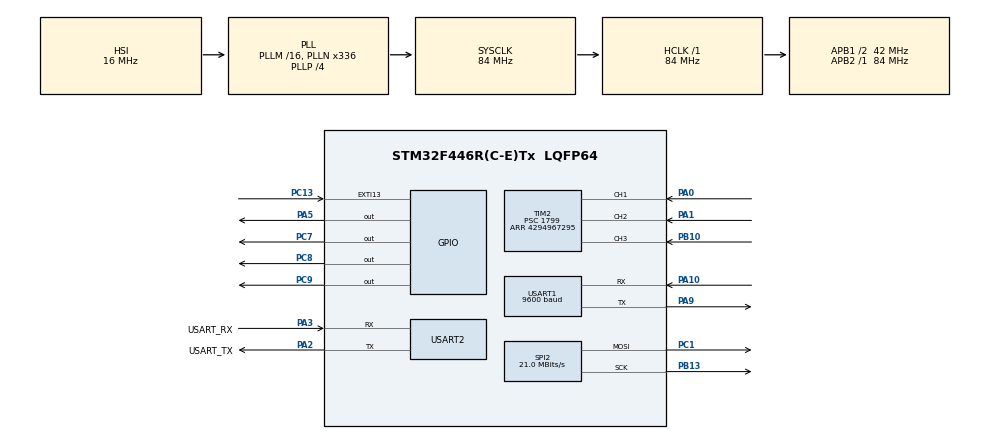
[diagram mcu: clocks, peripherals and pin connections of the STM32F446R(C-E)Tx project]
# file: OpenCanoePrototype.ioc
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Dma.Request0=USART2_TX
Dma.Request1=USART1_RX
Dma.USART1_RX.1.Direction=DMA_PERIPH_TO_MEMORY
Dma.USART1_RX.1.FIFOMode=DMA_FIFOMODE_DISABLE
Dma.USART1_RX.1.Instance=DMA2_Stream2
Dma.USART1_RX.1.MemDataAlignment=DMA_MDATAALIGN_BYTE
Dma.USART1_RX.1.MemInc=DMA_MINC_ENABLE
Dma.USART1_RX.1.Mode=DMA_CIRCULAR
Dma.USART1_RX.1.PeriphDataAlignment=DMA_PDATAALIGN_BYTE
Dma.USART1_RX.1.PeriphInc=DMA_PINC_DISABLE
Dma.USART1_RX.1.Priority=DMA_PRIORITY_LOW
Dma.USART2_TX.0.Direction=DMA_MEMORY_TO_PERIPH
Dma.USART2_TX.0.FIFOMode=DMA_FIFOMODE_DISABLE
Dma.USART2_TX.0.Instance=DMA1_Stream6
Dma.USART2_TX.0.MemDataAlignment=DMA_MDATAALIGN_BYTE
Dma.USART2_TX.0.MemInc=DMA_MINC_ENABLE
Dma.USART2_TX.0.Mode=DMA_NORMAL
Dma.USART2_TX.0.PeriphDataAlignment=DMA_PDATAALIGN_BYTE
Dma.USART2_TX.0.PeriphInc=DMA_PINC_DISABLE
Dma.USART2_TX.0.Priority=DMA_PRIORITY_LOW
Mcu.Family=STM32F4
Mcu.Name=STM32F446R(C-E)Tx
Mcu.Package=LQFP64
NUCLEO-F446RE.BUTTON=1
NUCLEO-F446RE.LD1=true
NVIC.DMA1_Stream6_IRQn=true\:0\:0\:false\:false\:true\:false\:true\:true
NVIC.DMA2_Stream2_IRQn=true\:0\:0\:false\:false\:true\:false\:true\:true
NVIC.EXTI15_10_IRQn=true\:0\:0\:false\:false\:true\:false\:true\:true
NVIC.PriorityGroup=NVIC_PRIORITYGROUP_0
NVIC.TIM2_IRQn=true\:0\:0\:false\:false\:true\:true\:true\:true
NVIC.USART1_IRQn=true\:0\:0\:false\:false\:true\:true\:true\:true
NVIC.USART2_IRQn=true\:0\:0\:false\:false\:true\:true\:true\:true
PA0-WKUP.GPIO_PuPd=GPIO_PULLDOWN
PA0-WKUP.Signal=S_TIM2_CH1_ETR
PA1.GPIO_PuPd=GPIO_PULLDOWN
PA1.Signal=S_TIM2_CH2
PA10.Mode=Asynchronous
PA10.Signal=USART1_RX
PA13.GPIO_Label=TMS
PA13.Signal=SYS_JTMS-SWDIO
PA14.GPIO_Label=TCK
PA14.Signal=SYS_JTCK-SWCLK
PA2.GPIO_Label=USART_TX
PA2.Mode=Asynchronous
PA2.Signal=USART2_TX
PA3.GPIO_Label=USART_RX
PA3.Mode=Asynchronous
PA3.Signal=USART2_RX
PA5.Signal=GPIO_Output
PA9.Mode=Asynchronous
PA9.Signal=USART1_TX
PB10.GPIO_PuPd=GPIO_PULLDOWN
PB10.Signal=S_TIM2_CH3
PB13.Mode=TX_Only_Simplex_Unidirect_Master
PB13.Signal=SPI2_SCK
PB3.GPIO_Label=SWO
PB3.Signal=SYS_JTDO-SWO
PC1.Mode=TX_Only_Simplex_Unidirect_Master
PC1.Signal=SPI2_MOSI
PC13.Signal=GPXTI13
PC14-OSC32_IN.Signal=RCC_OSC32_IN
PC15-OSC32_OUT.Signal=RCC_OSC32_OUT
PC7.Signal=GPIO_Output
PC8.Signal=GPIO_Output
PC9.Signal=GPIO_Output
PH0-OSC_IN.Signal=RCC_OSC_IN
PH1-OSC_OUT.Signal=RCC_OSC_OUT
ProjectManager.HeapSize=0x200
ProjectManager.StackSize=0x400
ProjectManager.TargetToolchain=CMake
RCC.AHBFreq_Value=84000000
RCC.APB1CLKDivider=RCC_HCLK_DIV2
RCC.APB1Freq_Value=42000000
RCC.APB1TimFreq_Value=84000000
RCC.APB2Freq_Value=84000000
RCC.APB2TimFreq_Value=84000000
RCC.CortexFreq_Value=84000000
RCC.FLatency-AdvancedSettings=FLASH_LATENCY_2
RCC.HCLKFreq_Value=84000000
RCC.HSE_VALUE=8000000
RCC.HSI_VALUE=16000000
RCC.LSE_VALUE=32768
RCC.PLLN=336
RCC.PLLP=RCC_PLLP_DIV4
RCC.SYSCLKFreq_VALUE=84000000
RCC.SYSCLKSource=RCC_SYSCLKSOURCE_PLLCLK
RCC.USBFreq_Value=168000000
RCC.VCOOutputFreq_Value=336000000
SH.S_TIM2_CH1_ETR.0=TIM2_CH1,TriggerSource_TI1FP1
SH.S_TIM2_CH1_ETR.1=TIM2_CH1,Input_Capture1_from_TI1
SH.S_TIM2_CH2.0=TIM2_CH2,Input_Capture2_from_TI2
SH.S_TIM2_CH3.0=TIM2_CH3,Input_Capture3_from_TI3
SPI2.CalculateBaudRate=21.0 MBits/s
SPI2.Direction=SPI_DIRECTION_2LINES
SPI2.Mode=SPI_MODE_MASTER
SPI2.VirtualType=VM_MASTER
TIM2.Channel-Input_Capture1_from_TI1=TIM_CHANNEL_1
TIM2.Channel-Input_Capture2_from_TI2=TIM_CHANNEL_2
TIM2.Channel-Input_Capture3_from_TI3=TIM_CHANNEL_3
TIM2.Period=4294967295
TIM2.Prescaler=1799
USART1.BaudRate=9600
USART1.VirtualMode=VM_ASYNC
USART2.VirtualMode=VM_ASYNC
VP_NUCLEO-F446RE_VS_BSP_COMMON.Mode=COMMON
VP_RTC_VS_RTC_Activate.Mode=RTC_Enabled
VP_RTC_VS_RTC_Calendar.Mode=RTC_Calendar
VP_TIM2_VS_ClockSourceINT.Mode=Internal
VP_TIM2_VS_ControllerModeReset.Mode=Reset Mode
board=NUCLEO-F446RE

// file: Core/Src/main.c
/* USER CODE BEGIN Header */
/**
 * @file main.c
 * @author Alexander Ellul (igsalexcodes@gmail.com)
 * @brief Prototype firmware application entry point.
 *
 * @copyright
 * Copyright (c) 2026 Alexander Ellul.
 *
 * SPDX-License-Identifier: GPL-3.0-only
 *
 * This file is part of the OpenCanoe Timing System prototype firmware.
 *
 * This software is licensed under the GNU General Public License v3.0.
 * See the LICENSE.md file in the root directory of this project for details.
 *
 * This software is provided "AS IS", WITHOUT WARRANTY OF ANY KIND,
 * either expressed or implied.
 *
 */
/* USER CODE END Header */
#include "main.h"

/* USER CODE BEGIN Includes */

#include "gnss.h"
#include "lcd.h"
#include "rtc.h"
#include "stm32f4xx_hal.h"
#include "uart.h"
#include <stdint.h>

/* USER CODE END Includes */

RTC_HandleTypeDef hrtc;

SPI_HandleTypeDef hspi2;

TIM_HandleTypeDef htim2;

UART_HandleTypeDef huart1;
UART_HandleTypeDef huart2;
DMA_HandleTypeDef hdma_usart1_rx;
DMA_HandleTypeDef hdma_usart2_tx;

void SystemClock_Config(void);
static void MX_GPIO_Init(void);
static void MX_DMA_Init(void);
static void MX_RTC_Init(void);
static void MX_TIM2_Init(void);
static void MX_USART2_UART_Init(void);
static void MX_USART1_UART_Init(void);
static void MX_SPI2_Init(void);

int main(void)
{

  /* MCU Configuration--------------------------------------------------------*/

  /* Reset of all peripherals, Initializes the Flash interface and the Systick. */
  HAL_Init();

  /* Configure the system clock */
  SystemClock_Config();

  /* Initialize all configured peripherals */
  MX_GPIO_Init();
  MX_DMA_Init();
  MX_RTC_Init();
  MX_TIM2_Init();
  MX_USART2_UART_Init();
  MX_USART1_UART_Init();
  MX_SPI2_Init();
  /* USER CODE BEGIN 2 */
  TIM_Init();

  /* UART_Init() must run after both USARTx inits and MX_DMA_Init(), since
   * it starts DMA reception on the ports that are configured for it.
   * GNSS_Init() then registers its NMEA handler on top of that, so it
   * must come after UART_Init(). */
  UART_Init();
  GNSS_Init();

  LCD_Init();
  LCD_FillScreen(LCD_BLACK);
  /* USER CODE END 2 */

  /* Initialize leds */
  BSP_LED_Init(LED2);

  /* Initialize USER push-button, will be used to trigger an interrupt each time it's pressed.*/
  BSP_PB_Init(BUTTON_USER, BUTTON_MODE_EXTI);

  /* Infinite loop */
  /* USER CODE BEGIN WHILE */
  while (1)
  {
    LCD_Process();
    /* USER CODE END WHILE */

  }
}

void SystemClock_Config(void)
{
  RCC_OscInitTypeDef RCC_OscInitStruct = {0};
  RCC_ClkInitTypeDef RCC_ClkInitStruct = {0};

  /** Configure the main internal regulator output voltage
  */
  __HAL_RCC_PWR_CLK_ENABLE();
  __HAL_PWR_VOLTAGESCALING_CONFIG(PWR_REGULATOR_VOLTAGE_SCALE3);

  /** Initializes the RCC Oscillators according to the specified parameters
  * in the RCC_OscInitTypeDef structure.
  */
  RCC_OscInitStruct.OscillatorType = RCC_OSCILLATORTYPE_HSI|RCC_OSCILLATORTYPE_LSI;
  RCC_OscInitStruct.LSEState = RCC_LSE_OFF;
  RCC_OscInitStruct.HSIState = RCC_HSI_ON;
  RCC_OscInitStruct.HSICalibrationValue = RCC_HSICALIBRATION_DEFAULT;
  RCC_OscInitStruct.LSIState = RCC_LSI_ON;
  RCC_OscInitStruct.PLL.PLLState = RCC_PLL_ON;
  RCC_OscInitStruct.PLL.PLLSource = RCC_PLLSOURCE_HSI;
  RCC_OscInitStruct.PLL.PLLM = 16;
  RCC_OscInitStruct.PLL.PLLN = 336;
  RCC_OscInitStruct.PLL.PLLP = RCC_PLLP_DIV4;
  RCC_OscInitStruct.PLL.PLLQ = 2;
  RCC_OscInitStruct.PLL.PLLR = 2;
  if (HAL_RCC_OscConfig(&RCC_OscInitStruct) != HAL_OK)
  {
    Error_Handler();
  }

  /** Initializes the CPU, AHB and APB buses clocks
  */
  RCC_ClkInitStruct.ClockType = RCC_CLOCKTYPE_HCLK|RCC_CLOCKTYPE_SYSCLK
                              |RCC_CLOCKTYPE_PCLK1|RCC_CLOCKTYPE_PCLK2;
  RCC_ClkInitStruct.SYSCLKSource = RCC_SYSCLKSOURCE_PLLCLK;
  RCC_ClkInitStruct.AHBCLKDivider = RCC_SYSCLK_DIV1;
  RCC_ClkInitStruct.APB1CLKDivider = RCC_HCLK_DIV2;
  RCC_ClkInitStruct.APB2CLKDivider = RCC_HCLK_DIV1;

  if (HAL_RCC_ClockConfig(&RCC_ClkInitStruct, FLASH_LATENCY_2) != HAL_OK)
  {
    Error_Handler();
  }
}

static void MX_RTC_Init(void)
{

  RTC_TimeTypeDef sTime = {0};
  RTC_DateTypeDef sDate = {0};

  /** Initialize RTC Only
  */
  hrtc.Instance = RTC;
  hrtc.Init.HourFormat = RTC_HOURFORMAT_24;
  hrtc.Init.AsynchPrediv = 127;
  hrtc.Init.SynchPrediv = 255;
  hrtc.Init.OutPut = RTC_OUTPUT_DISABLE;
  hrtc.Init.OutPutPolarity = RTC_OUTPUT_POLARITY_HIGH;
  hrtc.Init.OutPutType = RTC_OUTPUT_TYPE_OPENDRAIN;
  if (HAL_RTC_Init(&hrtc) != HAL_OK)
  {
    Error_Handler();
  }

  /** Initialize RTC and set the Time and Date
  */
  sTime.Hours = 0x0;
  sTime.Minutes = 0x0;
  sTime.Seconds = 0x0;
  sTime.DayLightSaving = RTC_DAYLIGHTSAVING_NONE;
  sTime.StoreOperation = RTC_STOREOPERATION_RESET;
  if (HAL_RTC_SetTime(&hrtc, &sTime, RTC_FORMAT_BCD) != HAL_OK)
  {
    Error_Handler();
  }
  sDate.WeekDay = RTC_WEEKDAY_MONDAY;
  sDate.Month = RTC_MONTH_JANUARY;
  sDate.Date = 0x1;
  sDate.Year = 0x0;

  if (HAL_RTC_SetDate(&hrtc, &sDate, RTC_FORMAT_BCD) != HAL_OK)
  {
    Error_Handler();
  }

}

static void MX_SPI2_Init(void)
{

  /* SPI2 parameter configuration*/
  hspi2.Instance = SPI2;
  hspi2.Init.Mode = SPI_MODE_MASTER;
  hspi2.Init.Direction = SPI_DIRECTION_2LINES;
  hspi2.Init.DataSize = SPI_DATASIZE_8BIT;
  hspi2.Init.CLKPolarity = SPI_POLARITY_LOW;
  hspi2.Init.CLKPhase = SPI_PHASE_1EDGE;
  hspi2.Init.NSS = SPI_NSS_SOFT;
  hspi2.Init.BaudRatePrescaler = SPI_BAUDRATEPRESCALER_2;
  hspi2.Init.FirstBit = SPI_FIRSTBIT_MSB;
  hspi2.Init.TIMode = SPI_TIMODE_DISABLE;
  hspi2.Init.CRCCalculation = SPI_CRCCALCULATION_DISABLE;
  hspi2.Init.CRCPolynomial = 10;
  if (HAL_SPI_Init(&hspi2) != HAL_OK)
  {
    Error_Handler();
  }

}

static void MX_TIM2_Init(void)
{

  TIM_ClockConfigTypeDef sClockSourceConfig = {0};
  TIM_SlaveConfigTypeDef sSlaveConfig = {0};
  TIM_MasterConfigTypeDef sMasterConfig = {0};
  TIM_IC_InitTypeDef sConfigIC = {0};

  htim2.Instance = TIM2;
  htim2.Init.Prescaler = 1799;
  htim2.Init.CounterMode = TIM_COUNTERMODE_UP;
  htim2.Init.Period = 4294967295;
  htim2.Init.ClockDivision = TIM_CLOCKDIVISION_DIV1;
  htim2.Init.AutoReloadPreload = TIM_AUTORELOAD_PRELOAD_DISABLE;
  if (HAL_TIM_Base_Init(&htim2) != HAL_OK)
  {
    Error_Handler();
  }
  sClockSourceConfig.ClockSource = TIM_CLOCKSOURCE_INTERNAL;
  if (HAL_TIM_ConfigClockSource(&htim2, &sClockSourceConfig) != HAL_OK)
  {
    Error_Handler();
  }
  if (HAL_TIM_IC_Init(&htim2) != HAL_OK)
  {
    Error_Handler();
  }
  sSlaveConfig.SlaveMode = TIM_SLAVEMODE_RESET;
  sSlaveConfig.InputTrigger = TIM_TS_TI1FP1;
  sSlaveConfig.TriggerPolarity = TIM_INPUTCHANNELPOLARITY_RISING;
  sSlaveConfig.TriggerFilter = 0;
  if (HAL_TIM_SlaveConfigSynchro(&htim2, &sSlaveConfig) != HAL_OK)
  {
    Error_Handler();
  }
  sMasterConfig.MasterOutputTrigger = TIM_TRGO_RESET;
  sMasterConfig.MasterSlaveMode = TIM_MASTERSLAVEMODE_DISABLE;
  if (HAL_TIMEx_MasterConfigSynchronization(&htim2, &sMasterConfig) != HAL_OK)
  {
    Error_Handler();
  }
  sConfigIC.ICPolarity = TIM_INPUTCHANNELPOLARITY_RISING;
  sConfigIC.ICSelection = TIM_ICSELECTION_DIRECTTI;
  sConfigIC.ICPrescaler = TIM_ICPSC_DIV1;
  sConfigIC.ICFilter = 0;
  if (HAL_TIM_IC_ConfigChannel(&htim2, &sConfigIC, TIM_CHANNEL_1) != HAL_OK)
  {
    Error_Handler();
  }
  if (HAL_TIM_IC_ConfigChannel(&htim2, &sConfigIC, TIM_CHANNEL_2) != HAL_OK)
  {
    Error_Handler();
  }
  if (HAL_TIM_IC_ConfigChannel(&htim2, &sConfigIC, TIM_CHANNEL_3) != HAL_OK)
  {
    Error_Handler();
  }

}

static void MX_USART1_UART_Init(void)
{

  huart1.Instance = USART1;
  huart1.Init.BaudRate = 9600;
  huart1.Init.WordLength = UART_WORDLENGTH_8B;
  huart1.Init.StopBits = UART_STOPBITS_1;
  huart1.Init.Parity = UART_PARITY_NONE;
  huart1.Init.Mode = UART_MODE_TX_RX;
  huart1.Init.HwFlowCtl = UART_HWCONTROL_NONE;
  huart1.Init.OverSampling = UART_OVERSAMPLING_16;
  if (HAL_UART_Init(&huart1) != HAL_OK)
  {
    Error_Handler();
  }

}

static void MX_USART2_UART_Init(void)
{

  huart2.Instance = USART2;
  huart2.Init.BaudRate = 115200;
  huart2.Init.WordLength = UART_WORDLENGTH_8B;
  huart2.Init.StopBits = UART_STOPBITS_1;
  huart2.Init.Parity = UART_PARITY_NONE;
  huart2.Init.Mode = UART_MODE_TX_RX;
  huart2.Init.HwFlowCtl = UART_HWCONTROL_NONE;
  huart2.Init.OverSampling = UART_OVERSAMPLING_16;
  if (HAL_UART_Init(&huart2) != HAL_OK)
  {
    Error_Handler();
  }

}

static void MX_DMA_Init(void)
{

  /* DMA controller clock enable */
  __HAL_RCC_DMA1_CLK_ENABLE();
  __HAL_RCC_DMA2_CLK_ENABLE();

  /* DMA interrupt init */
  /* DMA1_Stream6_IRQn interrupt configuration */
  HAL_NVIC_SetPriority(DMA1_Stream6_IRQn, 0, 0);
  HAL_NVIC_EnableIRQ(DMA1_Stream6_IRQn);
  /* DMA2_Stream2_IRQn interrupt configuration */
  HAL_NVIC_SetPriority(DMA2_Stream2_IRQn, 0, 0);
  HAL_NVIC_EnableIRQ(DMA2_Stream2_IRQn);

}

static void MX_GPIO_Init(void)
{
  GPIO_InitTypeDef GPIO_InitStruct = {0};

  /* GPIO Ports Clock Enable */
  __HAL_RCC_GPIOC_CLK_ENABLE();
  __HAL_RCC_GPIOH_CLK_ENABLE();
  __HAL_RCC_GPIOA_CLK_ENABLE();
  __HAL_RCC_GPIOB_CLK_ENABLE();

  /*Configure GPIO pin Output Level */
  HAL_GPIO_WritePin(GPIOC, GPIO_PIN_7|GPIO_PIN_8|GPIO_PIN_9, GPIO_PIN_RESET);

  /*Configure GPIO pins : PC7 PC8 PC9 */
  GPIO_InitStruct.Pin = GPIO_PIN_7|GPIO_PIN_8|GPIO_PIN_9;
  GPIO_InitStruct.Mode = GPIO_MODE_OUTPUT_PP;
  GPIO_InitStruct.Pull = GPIO_NOPULL;
  GPIO_InitStruct.Speed = GPIO_SPEED_FREQ_LOW;
  HAL_GPIO_Init(GPIOC, &GPIO_InitStruct);

}

void Error_Handler(void)
{
  __disable_irq();
  while (1)
  {
  }
}
